# R7FA4T1BB register map
Vendor: Renesas Electronics Corporation; Series: RA4; File version: 1.30.00
CPU: CM33 r0p4, little endian, MPU, FPU, VTOR, 4 interrupt priority bits, 96 interrupts
Registers are 32-bit, read-write, reset 0x0 unless marked. A register's access mark holds for its fields unless they carry their own. Offsets are from the block's base; [hi:lo] are bit positions; {n}, {i} and the like mark numbered series; 'fields as' and 'values as' point back to an identical list.

## CANFD_B — CANFD
Base 0x400B0000
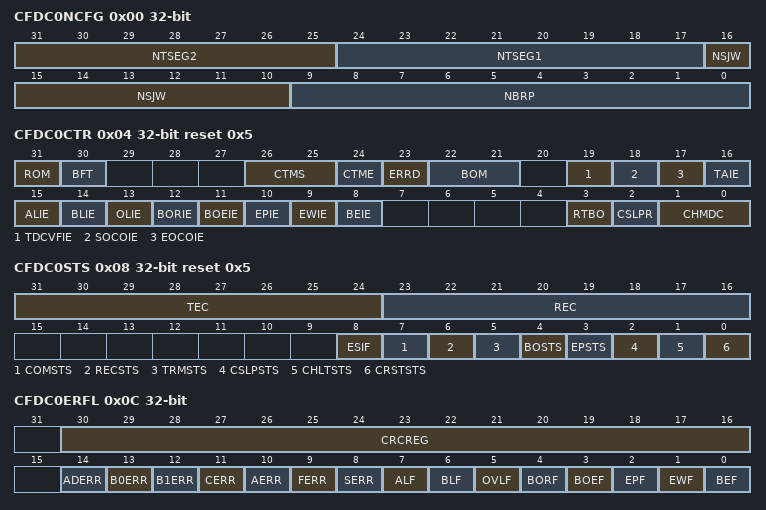
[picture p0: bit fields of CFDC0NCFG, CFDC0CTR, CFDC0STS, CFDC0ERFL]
0x00 CFDC0NCFG — Channel 0 Nominal Bitrate Configuration Register
  [31:25] NTSEG2 — Timing Segment 2
  [24:17] NTSEG1 — Timing Segment 1
  [16:10] NSJW — Resynchronization Jump Width
  [9:0] NBRP — Channel Nominal Baud Rate Prescaler
0x04 CFDC0CTR reset 0x5 — Channel 0 Control Register
  [31] ROM — Restricted Operation Mode
    0=Restricted operation mode disabled; 1=Restricted operation mode enabled
  [30] BFT — Bit Flip Test
    0=First data bit of reception stream not inverted; 1=First data bit of reception stream inverted
  [26:25] CTMS — Channel Test Mode Select
    0=Basic test mode; 1=Listen-only mode; 2=Self-test mode 0 (External loopback mode); 3=Self-test mode 1 (Internal loopback mode)
  [24] CTME — Channel Test Mode Enable
    0=Channel test mode disabled; 1=Channel test mode enabled
  [23] ERRD — Channel Error Display
    0=Only the first set of error codes displayed; 1=Accumulated error codes displayed
  [22:21] BOM — Channel Bus-Off Mode
    0=Normal mode (comply with ISO 11898-1); 1=Entry to Halt mode automatically at bus-off start; 2=Entry to Halt mode automatically at bus-off end; 3=Entry to Halt mode (during bus-off recovery period) by software
  [19] TDCVFIE — Transceiver Delay Compensation Violation Interrupt Enable
    0=Transceiver delay compensation violation interrupt disabled; 1=Transceiver delay compensation violation interrupt enabled
  [18] SOCOIE — Successful Occurrence Counter Overflow Interrupt Enable
    0=Successful occurrence counter overflow interrupt disabled; 1=Successful occurrence counter overflow interrupt enabled
  [17] EOCOIE — Error Occurrence Counter Overflow Interrupt Enable
    0=Error occurrence counter overflow interrupt disabled; 1=Error occurrence counter overflow interrupt enabled
  [16] TAIE — Transmission Abort Interrupt Enable
    0=TX abort interrupt disabled; 1=TX abort interrupt enabled
  [15] ALIE — Arbitration Lost Interrupt Enable
    0=Arbitration lost interrupt disabled; 1=Arbitration lost interrupt enabled
  [14] BLIE — Bus Lock Interrupt Enable
    0=Bus lock interrupt disabled; 1=Bus lock interrupt enabled
  [13] OLIE — Overload Interrupt Enable
    0=Overload interrupt disabled; 1=Overload interrupt enabled
  [12] BORIE — Bus-Off Recovery Interrupt Enable
    0=Bus-off recovery interrupt disabled; 1=Bus-off recovery interrupt enabled
  [11] BOEIE — Bus-Off Entry Interrupt Enable
    0=Bus-off entry interrupt disabled; 1=Bus-off entry interrupt enabled
  [10] EPIE — Error Passive Interrupt Enable
    0=Error passive interrupt disabled; 1=Error passive interrupt enabled
  [9] EWIE — Error Warning Interrupt Enable
    0=Error warning interrupt disabled; 1=Error warning interrupt enabled
  [8] BEIE — Bus Error Interrupt Enable
    0=Bus error interrupt disabled; 1=Bus error interrupt enabled
  [3] RTBO — Return from Bus-Off
    0=Channel is not forced to return from bus-off; 1=Channel is forced to return from bus-off
  [2] CSLPR — Channel Sleep Request
    0=Channel sleep request disabled; 1=Channel sleep request enabled
  [1:0] CHMDC — Channel Mode Control
    0=Channel operation mode request; 1=Channel reset request; 2=Channel halt request; 3=Keep current value
0x08 CFDC0STS reset 0x5 — Channel 0 Status Register
  [31:24] TEC ro — Transmission Error Count
  [23:16] REC ro — Reception Error Count
  [8] ESIF — Error State Indication Flag
    0=No CANFD message has been received when the ESI flag was set; 1=At least one CANFD message was received when the ESI flag was set
  [7] COMSTS ro — Channel Communication Status
    0=Channel is not ready for communication; 1=Channel is ready for communication
  [6] RECSTS ro — Channel Receive Status
    0=Channel is not receiving; 1=Channel is receiving
  [5] TRMSTS ro — Channel Transmit Status
    0=Channel is not transmitting; 1=Channel is transmitting
  [4] BOSTS ro — Channel Bus-Off Status
    0=Channel not in bus-off state; 1=Channel in bus-off state
  [3] EPSTS ro — Channel Error Passive Status
    0=Channel not in error passive state; 1=Channel in error passive state
  [2] CSLPSTS ro — Channel Sleep Status
    0=Channel not in Sleep mode; 1=Channel in Sleep mode
  [1] CHLTSTS ro — Channel Halt Status
    0=Channel not in Halt mode; 1=Channel in Halt mode
  [0] CRSTSTS ro — Channel Reset Status
    0=Channel not in Reset mode; 1=Channel in Reset mode
0x0C CFDC0ERFL — Channel 0 Error Flag Register
  [30:16] CRCREG ro — CRC Register value
  [14] ADERR — Acknowledge Delimiter Error
    0=Channel acknowledge delimiter error not detected; 1=Channel acknowledge delimiter error detected
  [13] B0ERR — Bit 0 Error
    0=Channel bit 0 error not detected; 1=Channel bit 0 error detected
  [12] B1ERR — Bit 1 Error
    0=Channel bit 1 error not detected; 1=Channel bit 1 error detected
  [11] CERR — CRC Error
    0=Channel CRC error not detected; 1=Channel CRC error detected
  [10] AERR — Acknowledge Error
    0=Channel acknowledge error not detected; 1=Channel acknowledge error detected
  [9] FERR — Form Error
    0=Channel form error not detected; 1=Channel form error detected
  [8] SERR — Stuff Error
    0=Channel stuff error not detected; 1=Channel stuff error detected
  [7] ALF — Arbitration Lost Flag
    0=Channel arbitration lost not detected; 1=Channel arbitration lost detected
  [6] BLF — Bus Lock Flag
    0=Channel bus lock not detected; 1=Channel bus lock detected
  [5] OVLF — Overload Flag
    0=Channel overload not detected; 1=Channel overload detected
  [4] BORF — Bus-Off Recovery Flag
    0=Channel bus-off recovery not detected; 1=Channel bus-off recovery detected
  [3] BOEF — Bus-Off Entry Flag
    0=Channel bus-off entry not detected; 1=Channel bus-off entry detected
  [2] EPF — Error Passive Flag
    0=Channel error passive not detected; 1=Channel error passive detected
  [1] EWF — Error Warning Flag
    0=Channel error warning not detected; 1=Channel error warning detected
  [0] BEF — Bus Error Flag
    0=Channel bus error not detected; 1=Channel bus error detected
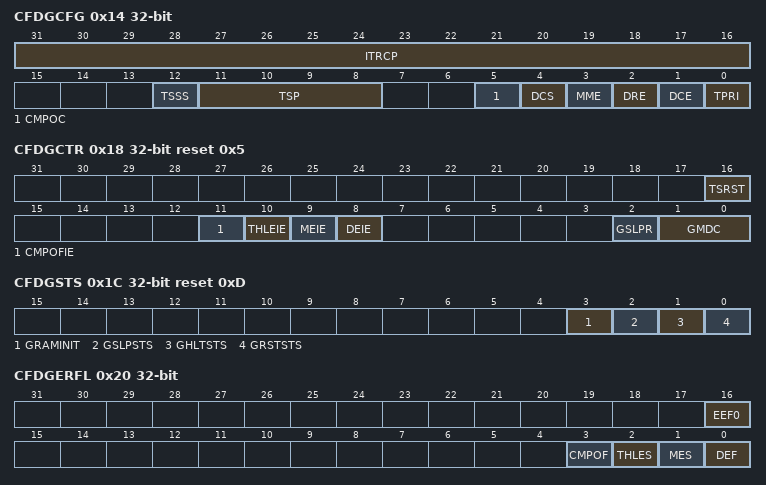
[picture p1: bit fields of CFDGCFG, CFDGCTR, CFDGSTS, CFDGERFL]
0x14 CFDGCFG — Global Configuration Register
  [31:16] ITRCP — Interval Timer Reference Clock Prescaler
  [12] TSSS — Timestamp Source Select
    0=Source clock for timestamp counter is peripheral clock; 1=Source clock for timestamp counter is bit time clock
  [11:8] TSP — Timestamp Prescaler
  [5] CMPOC — CANFD Message Payload Overflow Configuration
    0=Message is rejected; 1=Message payload is cut to fit to configured message size
  [4] DCS — Data Link Controller Clock Select
    0=Internal clean clock; 1=External clock source connected to CANMCLK pin
  [3] MME — Mirror Mode Enable
    0=Mirror mode disabled; 1=Mirror mode enabled
  [2] DRE — DLC Replacement Enable
    0=DLC replacement disabled; 1=DLC replacement enabled
  [1] DCE — DLC Check Enable
    0=DLC check disabled; 1=DLC check enabled
  [0] TPRI — Transmission Priority
    0=ID priority; 1=Message buffer number priority
0x18 CFDGCTR reset 0x5 — Global Control Register
  [16] TSRST — Timestamp Reset
    0=Timestamp not reset; 1=Timestamp reset
  [11] CMPOFIE — CANFD Message Payload Overflow Flag Interrupt Enable
    0=CANFD message payload overflow flag interrupt disabled; 1=CANFD message payload overflow flag interrupt enabled
  [10] THLEIE — TX History List Entry Lost Interrupt Enable
    0=TX history list entry lost interrupt disabled; 1=TX history list entry lost interrupt enabled
  [9] MEIE — Message Lost Error Interrupt Enable
    0=Message lost error interrupt disabled; 1=Message lost error interrupt enabled
  [8] DEIE — DLC Check Interrupt Enable
    0=DLC check interrupt disabled; 1=DLC check interrupt enabled
  [2] GSLPR — Global Sleep Request
    0=Global sleep request disabled; 1=Global sleep request enabled
  [1:0] GMDC — Global Mode Control
    0=Global operation mode request; 1=Global reset mode request; 2=Global halt mode request; 3=Keep current value
0x1C CFDGSTS ro reset 0xD — Global Status Register
  [3] GRAMINIT — Global RAM Initialization
    0=RAM initialization is complete; 1=RAM initialization is ongoing
  [2] GSLPSTS — Global Sleep Status
    0=Not in Sleep mode; 1=In Sleep mode
  [1] GHLTSTS — Global Halt Status
    0=Not in Halt mode; 1=In Halt mode
  [0] GRSTSTS — Global Reset Status
    0=Not in Reset mode; 1=In Reset mode
0x20 CFDGERFL — Global Error Flag Register
  [16] EEF0 — ECC Error Flag
    0=ECC error not detected during TX-SCAN; 1=ECC error detected during TX-SCAN
  [3] CMPOF — CANFD Message Payload Overflow Flag
    0=CANFD message payload overflow not detected; 1=CANFD message payload overflow detected
  [2] THLES ro — TX History List Entry Lost Error Status
    0=TX history list entry lost error not detected; 1=TX history list entry lost error detected
  [1] MES ro — Message Lost Error Status
    0=Message lost error not detected; 1=Message lost error detected
  [0] DEF — DLC Error Flag
    0=DLC error not detected; 1=DLC error detected
0x24 CFDGTSC ro — Global Timestamp Counter Register
  [15:0] TS — Timestamp value
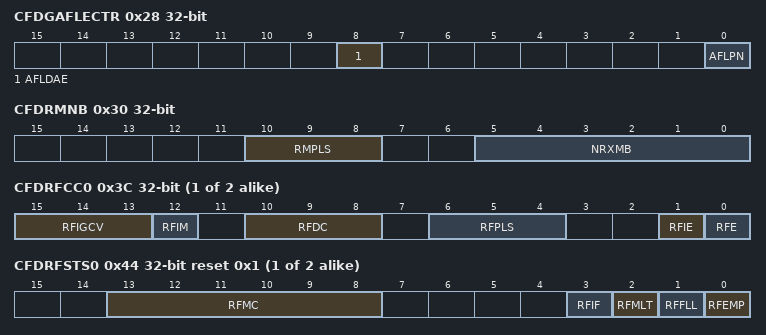
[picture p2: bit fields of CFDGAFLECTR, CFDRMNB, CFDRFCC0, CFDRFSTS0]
0x28 CFDGAFLECTR — Global Acceptance Filter List Entry Control Register
  [8] AFLDAE — Acceptance Filter List Data Access Enable
    0=Acceptance Filter List data access disabled; 1=Acceptance Filter List data access enabled
  [0] AFLPN — Acceptance Filter List Page Number
0x2C CFDGAFLCFG — Global Acceptance Filter List Configuration Register
  [21:16] RNC0 — Rule Number
0x30 CFDRMNB — RX Message Buffer Number Register
  [10:8] RMPLS — Reception Message Buffer Payload Data Size
    0=8 bytes; 1=12 bytes; 2=16 bytes; 3=20 bytes; 4=24 bytes; 5=32 bytes; 6=48 bytes; 7=64 bytes
  [5:0] NRXMB — Number of RX Message Buffers
0x34 CFDRMND — RX Message Buffer New Data Register
  [31:0] RMNS — RX Message Buffer New Data Status
    0=New data not stored in corresponding RX message buffer; 1=New data stored in corresponding RX message buffer
0x38 CFDRMIEC — RX Message Buffer Interrupt Enable Configuration Register
  [31:0] RMIEg — RX Message Buffer Interrupt Enable
    0=RX Message Buffer Interrupt disabled for corresponding RX message buffer; 1=RX Message Buffer Interrupt enabled for corresponding RX message buffer
{0x3C+4i} CFDRFCC{i} (i=0..1) — RX FIFO Configuration/Control Registers {i}
  [15:13] RFIGCV — RX FIFO Interrupt Generation Counter Value
    0=Interrupt generated when FIFO is 1/8th full; 1=Interrupt generated when FIFO is 1/4th full; 2=Interrupt generated when FIFO is 3/8th full; 3=Interrupt generated when FIFO is 1/2 full; 4=Interrupt generated when FIFO is 5/8th full; 5=Interrupt generated when FIFO is 3/4th full; 6=Interrupt generated when FIFO is 7/8th full; 7=Interrupt generated when FIFO is full
  [12] RFIM — RX FIFO Interrupt Mode
    0=Interrupt generated when RX FIFO counter reaches RFIGCV value from values smaller than RFIGCV; 1=Interrupt generated at the end of every received message storage
  [10:8] RFDC — RX FIFO Depth Configuration
    0=FIFO Depth = 0 message; 1=FIFO Depth = 4 messages; 2=FIFO Depth = 8 messages; 3=FIFO Depth = 16 messages; 4=FIFO Depth = 32 messages; 5=FIFO Depth = 48 messages
  [6:4] RFPLS — Rx FIFO Payload Data Size Configuration
    values as CFDRMNB.RMPLS
  [1] RFIE — RX FIFO Interrupt Enable
    0=FIFO interrupt generation disabled; 1=FIFO interrupt generation enabled
  [0] RFE — RX FIFO Enable
    0=FIFO disabled; 1=FIFO enabled
{0x44+4i} CFDRFSTS{i} (i=0..1) reset 0x1 — RX FIFO Status Registers {i}
  [13:8] RFMC ro — RX FIFO Message Count
  [3] RFIF — RX FIFO Interrupt Flag
    0=FIFO interrupt condition not satisfied; 1=FIFO interrupt condition satisfied
  [2] RFMLT — RX FIFO Message Lost
    0=No message lost in FIFO; 1=FIFO message lost
  [1] RFFLL ro — RX FIFO Full
    0=FIFO not full; 1=FIFO full
  [0] RFEMP ro — RX FIFO Empty
    0=FIFO not empty; 1=FIFO empty
{0x4C+4i} CFDRFPCTR{i} (i=0..1) wo — RX FIFO Pointer Control Registers {i}
  [7:0] RFPC — RX FIFO Pointer Control
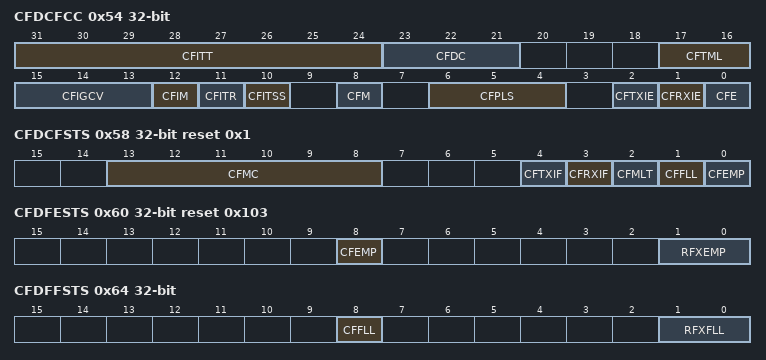
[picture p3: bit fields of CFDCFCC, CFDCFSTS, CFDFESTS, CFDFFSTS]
0x54 CFDCFCC — Common FIFO Configuration/Control Register
  [31:24] CFITT — Common FIFO Interval Transmission Time
  [23:21] CFDC — Common FIFO Depth Configuration
    0=FIFO Depth = 0 message; 1=FIFO Depth = 4 messages; 2=FIFO Depth = 8 messages; 3=FIFO Depth = 16 messages; 4=FIFO Depth = 32 messages; 5=FIFO Depth = 48 messages; 6=FIFO Depth = Reserved; 7=FIFO Depth = Reserved
  [17:16] CFTML — Common FIFO TX Message Buffer Link
  [15:13] CFIGCV — Common FIFO Interrupt Generation Counter Value
    values as CFDRFCC0.RFIGCV
  [12] CFIM — Common FIFO Interrupt Mode
    0=RX FIFO mode: RX interrupt generated when Common FIFO counter reaches CFIGCV value from a lower value TX FIFO mode: TX interrupt generated when Common FIFO transmits the last message successfully; 1=RX FIFO mode: RX interrupt generated at the end of every received message storage TX FIFO mode: interrupt generated for every successfully transmitted message
  [11] CFITR — Common FIFO Interval Timer Resolution
    0=Reference clock period × 1; 1=Reference clock period × 10
  [10] CFITSS — Common FIFO Interval Timer Source Select
    0=Reference clock (× 1 / × 10 period); 1=Bit time clock of related channel (FIFO is linked to fixed channel)
  [8] CFM — Common FIFO Mode
    0=RX FIFO mode; 1=TX FIFO mode
  [6:4] CFPLS — Common FIFO Payload Data Size Configuration
    values as CFDRMNB.RMPLS
  [2] CFTXIE — Common FIFO TX Interrupt Enable
    0=FIFO interrupt generation disabled for Frame TX; 1=FIFO interrupt generation enabled for Frame TX
  [1] CFRXIE — Common FIFO RX Interrupt Enable
    0=FIFO interrupt generation disabled for Frame RX; 1=FIFO interrupt generation enabled for Frame RX
  [0] CFE — Common FIFO Enable
    0=FIFO disabled; 1=FIFO enabled
0x58 CFDCFSTS reset 0x1 — Common FIFO Status Register
  [13:8] CFMC ro — Common FIFO Message Count
  [4] CFTXIF — Common TX FIFO Interrupt Flag
    0=FIFO interrupt condition not satisfied after frame transmission; 1=FIFO Interrupt condition satisfied after frame transmission
  [3] CFRXIF — Common RX FIFO Interrupt Flag
    0=FIFO interrupt condition not satisfied after frame reception; 1=FIFO interrupt condition satisfied after frame reception
  [2] CFMLT — Common FIFO Message Lost
    0=Number of message lost in FIFO; 1=FIFO message lost
  [1] CFFLL ro — Common FIFO Full
    0=FIFO not full; 1=FIFO full
  [0] CFEMP ro — Common FIFO Empty
    0=FIFO not empty; 1=FIFO empty
0x5C CFDCFPCTR wo — Common FIFO Pointer Control Register
  [7:0] CFPC — Common FIFO Pointer Control
0x60 CFDFESTS ro reset 0x103 — FIFO Empty Status Register
  [8] CFEMP — Common FIFO Empty Status
    0=Corresponding FIFO not empty; 1=Corresponding FIFO empty
  [1:0] RFXEMP — RX FIFO Empty Status
    0=Corresponding FIFO not empty; 1=Corresponding FIFO empty
0x64 CFDFFSTS ro — FIFO Full Status Register
  [8] CFFLL — Common FIF0 Full Status
    0=Corresponding FIFO not full; 1=Corresponding FIFO full
  [1:0] RFXFLL — RX FIF0 Full Status
    0=Corresponding FIFO not full; 1=Corresponding FIFO full
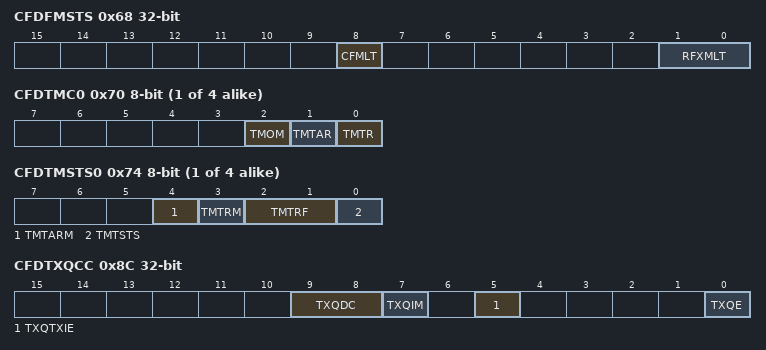
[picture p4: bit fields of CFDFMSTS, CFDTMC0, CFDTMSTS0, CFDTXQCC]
0x68 CFDFMSTS ro — FIFO Message Lost Status Register
  [8] CFMLT — Common FIFO Message Lost Status
    0=Corresponding FIFO Message Lost flag not set; 1=Corresponding FIFO Message Lost flag set
  [1:0] RFXMLT — RX FIFO Message Lost Status
    values as CFMLT
0x6C CFDRFISTS ro — RX FIFO Interrupt Flag Status Register
  [1:0] RFXIF — RX FIFO[x] Interrupt Flag Status
    0=Corresponding RX FIFO Interrupt flag not set; 1=Corresponding RX FIFO Interrupt flag set
{0x70+i} CFDTMC{i} (i=0..3) 8-bit — TX Message Buffer Control Registers {i}
  [2] TMOM — TX Message Buffer One-shot Mode
    0=TX message buffer not configured in one-shot mode; 1=TX message buffer configured in one-shot mode
  [1] TMTAR — TX Message Buffer Transmission Abort Request
    0=TX message buffer transmission request abort not requested; 1=TX message buffer transmission request abort requested
  [0] TMTR — TX Message Buffer Transmission Request
    0=TX Message buffer transmission not requested; 1=TX message buffer transmission requested
{0x74+i} CFDTMSTS{i} (i=0..3) 8-bit — TX Message Buffer Status Registers {i}
  [4] TMTARM ro — TX Message Buffer Transmission Abort Request Mirrored
    values as CFDTMC0.TMTAR
  [3] TMTRM ro — TX Message Buffer Transmission Request Mirrored
    0=TX message buffer transmission not requested; 1=TX message buffer transmission requested
  [2:1] TMTRF — TX Message Buffer Transmission Result Flag
    0=No result; 1=Transmission aborted from the TX message buffer; 2=Transmission successful from the TX message buffer and transmission abort was not requested; 3=Transmission successful from the TX message buffer and transmission abort was requested
  [0] TMTSTS ro — TX Message Buffer Transmission Status
    0=No on-going transmission; 1=On-going transmission
0x78 CFDTMTRSTS ro — TX Message Buffer Transmission Request Status Register
  [3:0] CFDTMTRSTS — TX Message Buffer Transmission Request Status
    0=Transmission not requested for corresponding TX message buffer; 1=Transmission requested for corresponding TX message buffer
0x7C CFDTMTARSTS ro — TX Message Buffer Transmission Abort Request Status Register
  [3:0] CFDTMTARSTS — TX Message Buffer Transmission Abort Request Status
    0=Transmission abort not requested for corresponding TX message buffer; 1=Transmission abort requested for corresponding TX message buffer
0x80 CFDTMTCSTS ro — TX Message Buffer Transmission Completion Status Register
  [3:0] CFDTMTCSTS — TX Message Buffer Transmission Completion Status
    0=Transmission not complete for corresponding TX message buffer; 1=Transmission completed for corresponding TX message buffer
0x84 CFDTMTASTS ro — TX Message Buffer Transmission Abort Status Register
  [3:0] CFDTMTASTS — TX Message Buffer Transmission Abort Status
    0=Transmission not aborted for corresponding TX message buffer; 1=Transmission aborted for corresponding TX message buffer
0x88 CFDTMIEC — TX Message Buffer Interrupt Enable Configuration Register
  [3:0] TMIEg — TX Message Buffer Interrupt Enable
    0=TX message buffer interrupt disabled for corresponding TX message buffer; 1=TX message buffer interrupt enabled for corresponding TX message buffer
0x8C CFDTXQCC — TX Queue Configuration/Control Register
  [9:8] TXQDC — TX Queue Depth Configuration
    0=0 messages; 16=3 messages; 17=4 messages
  [7] TXQIM — TX Queue Interrupt Mode
    0=When the last message is successfully transmitted; 1=At every successful transmission
  [5] TXQTXIE — TX Queue TX Interrupt Enable
    0=TX Queue TX interrupt disabled; 1=TX Queue TX interrupt enabled
  [0] TXQE — TX Queue Enable
    0=TX Queue disabled; 1=TX Queue enabled
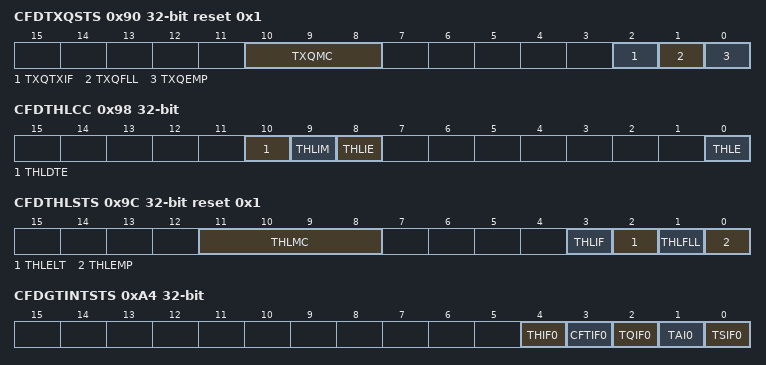
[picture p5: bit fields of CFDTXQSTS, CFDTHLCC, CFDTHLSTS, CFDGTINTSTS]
0x90 CFDTXQSTS reset 0x1 — TX Queue Status Register
  [10:8] TXQMC ro — TX Queue Message Count
  [2] TXQTXIF — TX Queue TX Interrupt Flag
    0=TX Queue interrupt condition not satisfied after a frame TX; 1=TX Queue interrupt condition satisfied after a frame TX
  [1] TXQFLL ro — TX Queue Full
    0=TX Queue not full; 1=TX Queue full
  [0] TXQEMP ro — TX Queue Empty
    0=TX Queue not empty; 1=TX Queue empty
0x94 CFDTXQPCTR — TX Queue Pointer Control Register
  [7:0] TXQPC wo — TX Queue Pointer Control
0x98 CFDTHLCC — TX History List Configuration/Control Register
  [10] THLDTE — TX History List Dedicated TX Enable
    0=TX FIFO + TX Queue; 1=Flat TX MB + TX FIFO + TX Queue
  [9] THLIM — TX History List Interrupt Mode
    0=Interrupt generated if TX History List level reaches ¾ of the TX History List depth; 1=Interrupt generated for every successfully stored entry
  [8] THLIE — TX History List Interrupt Enable
    0=TX History List Interrupt disabled; 1=TX History List Interrupt enabled
  [0] THLE — TX History List Enable
    0=TX History List disabled; 1=TX History List enabled
0x9C CFDTHLSTS reset 0x1 — TX History List Status Register
  [11:8] THLMC ro — TX History List Message Count
  [3] THLIF — TX History List Interrupt Flag
    0=TX History List interrupt condition not satisfied; 1=TX History List interrupt condition satisfied
  [2] THLELT — TX History List Entry Lost
    0=No entry lost in TX History List; 1=TX History List entry Lost
  [1] THLFLL ro — TX History List Full
    0=TX History List not full; 1=TX History List full
  [0] THLEMP ro — TX History List Empty
    0=TX History List not empty; 1=TX History List empty
0xA0 CFDTHLPCTR wo — TX History List Pointer Control Register
  [7:0] THLPC — TX History List Pointer Control
0xA4 CFDGTINTSTS ro — Global TX Interrupt Status Register
  [4] THIF0 — TX History List Interrupt
    0=Channel n TX History List Interrupt flag not set; 1=Channel n TX History List Interrupt flag set
  [3] CFTIF0 — COM FIFO TX Mode Interrupt Flag
    0=Channel n COM FIFO TX Mode Interrupt flag not set; 1=Channel n COM FIFO TX Mode Interrupt flag set
  [2] TQIF0 — TX Queue Interrupt Flag
    0=Channel n TX Queue Interrupt flag not set; 1=Channel n TX Queue Interrupt flag set
  [1] TAI0 — TX Abort Interrupt Flag
    0=Channel n TX Abort Interrupt flag not set; 1=Channel n TX Abort Interrupt flag set
  [0] TSIF0 — TX Successful Interrupt Flag
    0=Channel n TX Successful Interrupt flag not set; 1=Channel n TX Successful Interrupt flag set
0xA8 CFDGTSTCFG — Global Test Configuration Register
  [19:16] RTMPS — RAM Test Mode Page Select
0xAC CFDGTSTCTR — Global Test Control Register
  [2] RTME — RAM Test Mode Enable
    0=RAM test mode disabled; 1=RAM test mode enabled
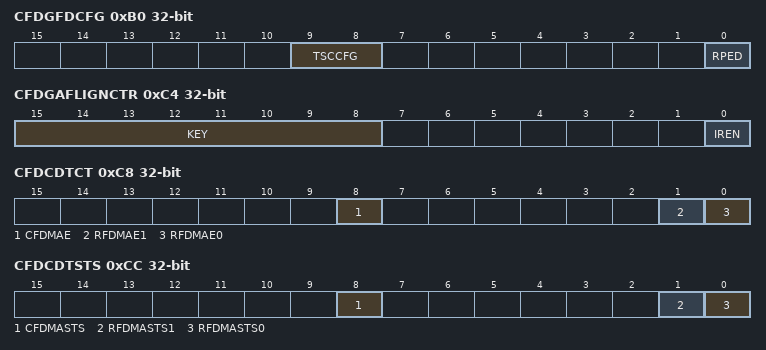
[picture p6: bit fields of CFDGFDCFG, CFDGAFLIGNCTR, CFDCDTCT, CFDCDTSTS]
0xB0 CFDGFDCFG — Global FD Configuration Register
  [9:8] TSCCFG — Timestamp Capture Configuration
    0=Timestamp capture at the sample point of SOF (start of frame); 1=Timestamp capture at frame valid indication; 2=Timestamp capture at the sample point of RES bit
  [0] RPED — RES Bit Protocol Exception Disable
    0=Protocol exception event detection enabled; 1=Protocol exception event detection disabled
0xB8 CFDGLOCKK wo — Global Lock Key Register
  [15:0] LOCK — Lock Key
0xC0 CFDGAFLIGNENT — Global AFL Ignore Entry Register
  [4:0] IRN — Ignore Rule Number
0xC4 CFDGAFLIGNCTR — Global AFL Ignore Control Register
  [15:8] KEY wo — Key Code
  [0] IREN — Ignore Rule Enable
    0=AFL entry number is not ignored; 1=AFL entry number is ignored
0xC8 CFDCDTCT — DMA Transfer Control Register
  [all] fields
    0=DMA transfer request disabled; 1=DMA transfer request enabled
  [8] CFDMAE — DMA Transfer Enable for Common FIFO 0
  [1] RFDMAE1 — DMA Transfer Enable for RXFIFO 1
  [0] RFDMAE0 — DMA Transfer Enable for RXFIFO 0
0xCC CFDCDTSTS ro — DMA Transfer Status Register
  [all] fields
    0=DMA transfer stopped; 1=DMA transfer on going
  [8] CFDMASTS — DMA Transfer Status only for Common FIFO
  [1] RFDMASTS1 — DMA Transfer Status for RX FIFO 1
  [0] RFDMASTS0 — DMA Transfer Status for RX FIFO 0
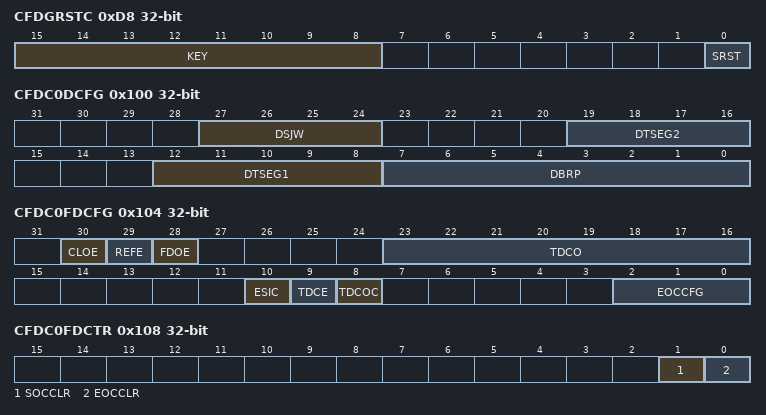
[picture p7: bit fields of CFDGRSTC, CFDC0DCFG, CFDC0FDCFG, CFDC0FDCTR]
0xD8 CFDGRSTC — Global SW reset Register
  [15:8] KEY wo — Key Code
  [0] SRST — SW Reset
    0=Normal state; 1=SW reset state
0x100 CFDC0DCFG — Channel 0 Data Bitrate Configuration Register
  [27:24] DSJW — Resynchronization Jump Width
  [19:16] DTSEG2 — Timing Segment 2
  [12:8] DTSEG1 — Timing Segment 1
  [7:0] DBRP — Channel Data Baud Rate Prescaler
0x104 CFDC0FDCFG — Channel 0 CANFD Configuration Register
  [30] CLOE — Classical CAN Enable
    0=Classical CAN mode disabled; 1=Classical CAN mode enabled
  [29] REFE — RX Edge Filter Enable
    0=RX edge filter disabled; 1=RX edge filter enabled
  [28] FDOE — FD-Only Enable
    0=FD-only mode disabled; 1=FD-only mode enabled
  [23:16] TDCO — Transceiver Delay Compensation Offset
  [10] ESIC — Error State Indication Configuration
    0=The ESI bit in the frame represents the error state of the node itself; 1=The ESI bit in the frame represents the error state of the message buffer if the node itself is not in error passive. If the node is in error passive, then the ESI bit is driven by the node itself.
  [9] TDCE — Transceiver Delay Compensation Enable
    0=Transceiver delay compensation disabled; 1=Transceiver delay compensation enabled
  [8] TDCOC — Transceiver Delay Compensation Offset Configuration
    0=Measured + offset; 1=Offset-only
  [2:0] EOCCFG — Error Occurrence Counter Configuration
    0=All transmitter or receiver CAN frames; 1=All transmitter CAN frames; 2=All receiver CAN frames; 4=Only transmitter or receiver CANFD data-phase (fast bits); 5=Only transmitter CANFD data-phase (fast bits); 6=Only receiver CANFD data-phase (fast bits)
0x108 CFDC0FDCTR — Channel 0 CANFD Control Register
  [1] SOCCLR — Successful Occurrence Counter Clear
    0=No successful occurrence counter clear; 1=Clear successful occurrence counter
  [0] EOCCLR — Error Occurrence Counter Clear
    0=No error occurrence counter clear; 1=Clear error occurrence counter
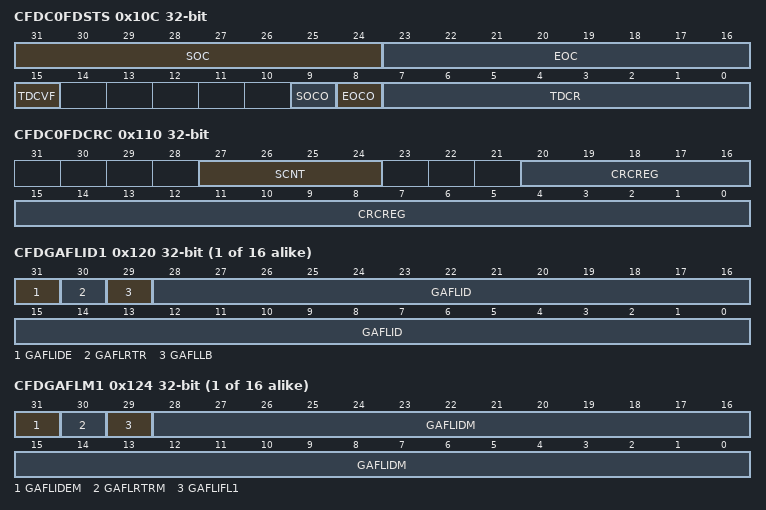
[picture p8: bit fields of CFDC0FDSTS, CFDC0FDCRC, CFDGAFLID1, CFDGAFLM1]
0x10C CFDC0FDSTS — Channel 0 CANFD Status Register
  [31:24] SOC ro — Successful occurrence counter
  [23:16] EOC ro — Error Occurrence Counter
  [15] TDCVF — Transceiver Delay Compensation Violation Flag
    0=Transceiver delay compensation violation has not occurred; 1=Transceiver delay compensation violation has occurred
  [9] SOCO — Successful Occurrence Counter Overflow
    0=Successful occurrence counter has not overflowed; 1=Successful occurrence counter has overflowed
  [8] EOCO — Error Occurrence Counter Overflow
    0=Error occurrence counter has not overflowed; 1=Error occurrence counter has overflowed
  [7:0] TDCR ro — Transceiver Delay Compensation Result
0x110 CFDC0FDCRC — Channel 0 CANFD CRC Register
  [27:24] SCNT ro — Stuff bit count
  [20:0] CRCREG ro — CRC Register value
{0x110+0x10*i} CFDGAFLID{i} (i=1..16) — Global Acceptance Filter List ID Registers
  [31] GAFLIDE — Global Acceptance Filter List Entry IDE Field
    0=Standard identifier of rule entry ID is valid for acceptance filtering; 1=Extended identifier of rule entry ID is valid for acceptance filtering
  [30] GAFLRTR — Global Acceptance Filter List Entry RTR Field
    0=Data frame; 1=Remote frame
  [29] GAFLLB — Global Acceptance Filter List Entry Loopback Configuration
    0=Global Acceptance Filter List entry ID for acceptance filtering with attribute RX; 1=Global Acceptance Filter List entry ID for acceptance filtering with attribute TX
  [28:0] GAFLID — Global Acceptance Filter List Entry ID Field
{0x114+0x10*i} CFDGAFLM{i} (i=1..16) — Global Acceptance Filter List Mask Registers
  [31] GAFLIDEM — Global Acceptance Filter List IDE Mask
    0=IDE bit is not used for ID matching; 1=IDE bit is used for ID matching
  [30] GAFLRTRM — Global Acceptance Filter List Entry RTR Mask
    0=RTR bit is not used for ID matching; 1=RTR bit is used for ID matching
  [29] GAFLIFL1 — Global Acceptance Filter List Information Label 1
  [28:0] GAFLIDM — Global Acceptance Filter List ID Mask Field
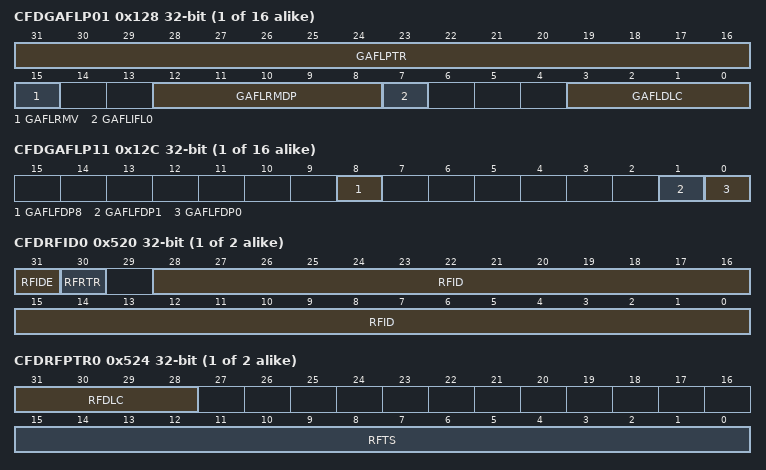
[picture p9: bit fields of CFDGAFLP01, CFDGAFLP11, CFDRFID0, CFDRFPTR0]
{0x118+0x10*i} CFDGAFLP0{i} (i=1..16) — Global Acceptance Filter List Pointer 0 Registers
  [31:16] GAFLPTR — Global Acceptance Filter List Pointer
  [15] GAFLRMV — Global Acceptance Filter List RX Message Buffer Valid
    0=Single message buffer direction pointer is invalid; 1=Single message buffer direction pointer is valid
  [12:8] GAFLRMDP — Global Acceptance Filter List RX Message Buffer Direction Pointer
  [7] GAFLIFL0 — Global Acceptance Filter List Information Label 0
  [3:0] GAFLDLC — Global Acceptance Filter List DLC Field
{0x11C+0x10*i} CFDGAFLP1{i} (i=1..16) — Global Acceptance Filter List Pointer 1 Registers
  [8] GAFLFDP8 — Global Acceptance Filter List FIFO Direction Pointer
    0=Disable Common FIFO as target for reception; 1=Enable Common FIFO as target for reception
  [1] GAFLFDP1 — Global Acceptance Filter List FIFO Direction Pointer
    0=Disable RX FIFO 1 as target for reception; 1=Enable RX FIFO 1 as target for reception
  [0] GAFLFDP0 — Global Acceptance Filter List FIFO Direction Pointer
    0=Disable RX FIFO 0 as target for reception; 1=Enable RX FIFO 0 as target for reception
{0x280+4i} CFDRPGACC{i} (i=0..63) — RAM Test Page Access Registers {i}
  [31:0] RDTA — RAM Data Test Access
{0x520+0x4C*i} CFDRFID{i} (i=0..1) ro — RX FIFO Access ID Register {i}
  [31] RFIDE — RX FIFO Buffer IDE bit
    0=STD-ID has been received; 1=EXT-ID has been received
  [30] RFRTR — RX FIFO Buffer RTR bit
    0=Data frame; 1=Remote frame
  [28:0] RFID — RX FIFO Buffer ID Field
{0x524+0x4C*i} CFDRFPTR{i} (i=0..1) ro — RX FIFO Access Pointer Register {i}
  [31:28] RFDLC — RX FIFO Buffer DLC Field
  [15:0] RFTS — RX FIFO Timestamp Value
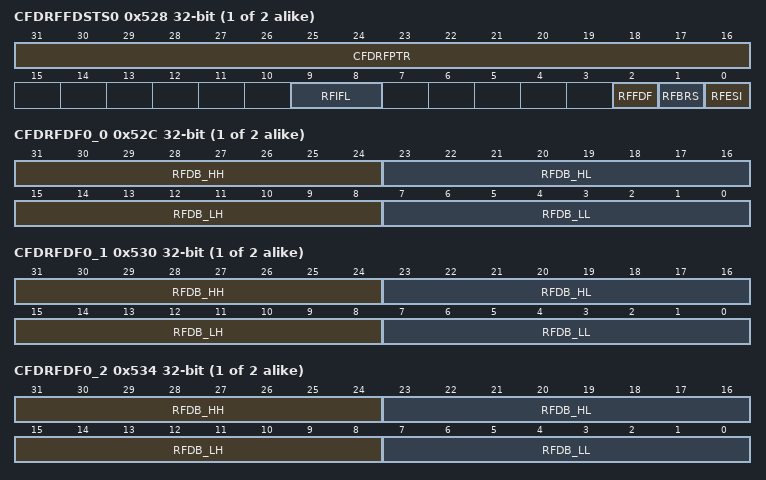
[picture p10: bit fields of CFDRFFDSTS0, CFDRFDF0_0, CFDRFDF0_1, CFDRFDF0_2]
{0x528+0x4C*i} CFDRFFDSTS{i} (i=0..1) ro — RX FIFO Access CANFD Status Register {i}
  [31:16] CFDRFPTR — RX FIFO Buffer Pointer Field
  [9:8] RFIFL — RX FIFO Buffer Information Label Field
  [2] RFFDF — CAN FD Format bit
    0=Non CANFD frame received; 1=CANFD frame received
  [1] RFBRS — Bit Rate Switch bit
    0=CANFD frame received with no bit rate switch; 1=CANFD frame received with bit rate switch
  [0] RFESI — Error State Indicator bit
    0=CANFD frame received from error active node; 1=CANFD frame received from error passive node
{0x52C+0x4C*i} CFDRFDF{i}_0 (i=0..1) ro — RX FIFO Access Data Field 0 Register {i}
  [31:24] RFDB_HH — RX FIFO Buffer Data Byte ((p × 4) + 3)
  [23:16] RFDB_HL — RX FIFO Buffer Data Byte ((p × 4) + 2)
  [15:8] RFDB_LH — RX FIFO Buffer Data Byte ((p × 4) + 1)
  [7:0] RFDB_LL — RX FIFO Buffer Data Byte (p × 4)
{0x530+0x4C*i} CFDRFDF{i}_1 (i=0..1) ro — RX FIFO Access Data Field 1 Register {i}
  fields as CFDRFDF0_0
{0x534+0x4C*i} CFDRFDF{i}_2 (i=0..1) ro — RX FIFO Access Data Field 2 Register {i}
  fields as CFDRFDF0_0
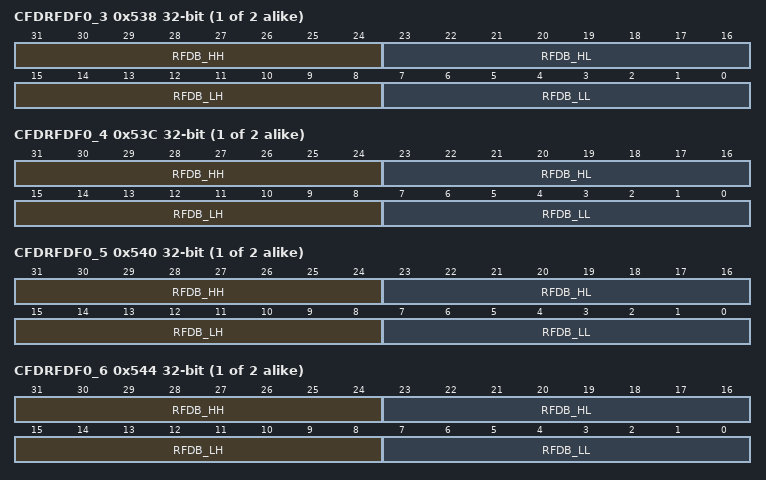
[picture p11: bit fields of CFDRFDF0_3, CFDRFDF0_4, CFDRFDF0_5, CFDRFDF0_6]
{0x538+0x4C*i} CFDRFDF{i}_3 (i=0..1) ro — RX FIFO Access Data Field 3 Register {i}
  fields as CFDRFDF0_0
{0x53C+0x4C*i} CFDRFDF{i}_4 (i=0..1) ro — RX FIFO Access Data Field 4 Register {i}
  fields as CFDRFDF0_0
{0x540+0x4C*i} CFDRFDF{i}_5 (i=0..1) ro — RX FIFO Access Data Field 5 Register {i}
  fields as CFDRFDF0_0
{0x544+0x4C*i} CFDRFDF{i}_6 (i=0..1) ro — RX FIFO Access Data Field 6 Register {i}
  fields as CFDRFDF0_0
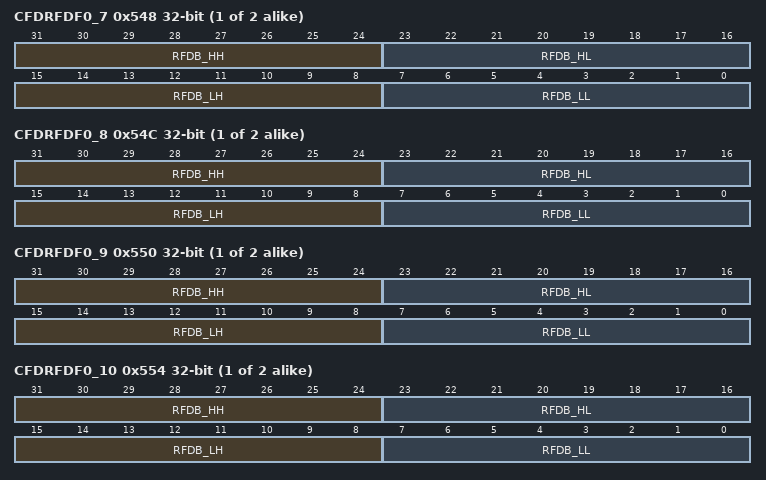
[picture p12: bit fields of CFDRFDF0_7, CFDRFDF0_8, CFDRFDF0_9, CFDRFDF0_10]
{0x548+0x4C*i} CFDRFDF{i}_7 (i=0..1) ro — RX FIFO Access Data Field 7 Register {i}
  fields as CFDRFDF0_0
{0x54C+0x4C*i} CFDRFDF{i}_8 (i=0..1) ro — RX FIFO Access Data Field 8 Register {i}
  fields as CFDRFDF0_0
{0x550+0x4C*i} CFDRFDF{i}_9 (i=0..1) ro — RX FIFO Access Data Field 9 Register {i}
  fields as CFDRFDF0_0
{0x554+0x4C*i} CFDRFDF{i}_10 (i=0..1) ro — RX FIFO Access Data Field 10 Register {i}
  fields as CFDRFDF0_0
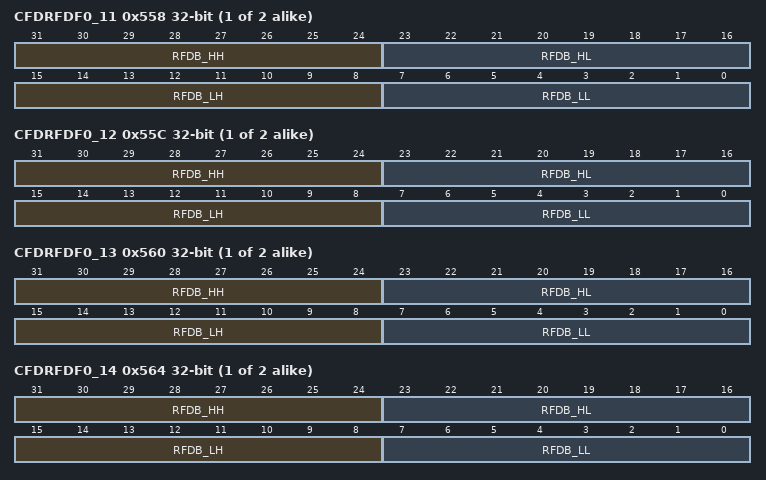
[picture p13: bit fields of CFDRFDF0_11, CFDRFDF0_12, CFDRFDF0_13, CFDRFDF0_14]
{0x558+0x4C*i} CFDRFDF{i}_11 (i=0..1) ro — RX FIFO Access Data Field 11 Register {i}
  fields as CFDRFDF0_0
{0x55C+0x4C*i} CFDRFDF{i}_12 (i=0..1) ro — RX FIFO Access Data Field 12 Register {i}
  fields as CFDRFDF0_0
{0x560+0x4C*i} CFDRFDF{i}_13 (i=0..1) ro — RX FIFO Access Data Field 13 Register {i}
  fields as CFDRFDF0_0
{0x564+0x4C*i} CFDRFDF{i}_14 (i=0..1) ro — RX FIFO Access Data Field 14 Register {i}
  fields as CFDRFDF0_0
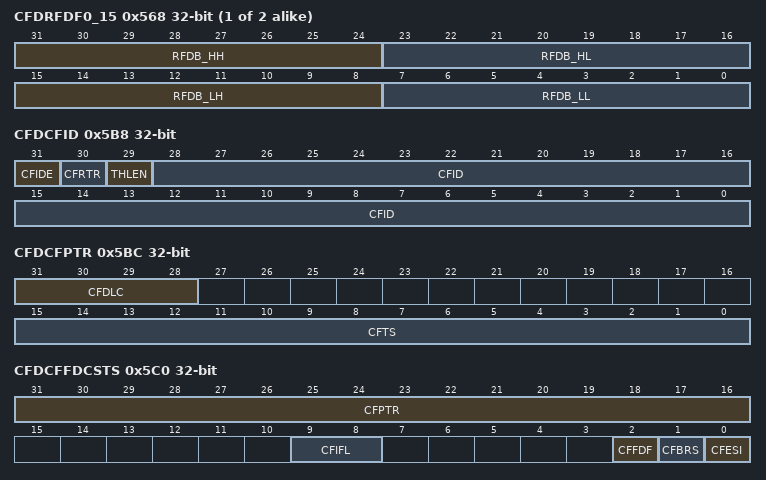
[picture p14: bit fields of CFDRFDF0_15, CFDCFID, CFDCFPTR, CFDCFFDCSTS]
{0x568+0x4C*i} CFDRFDF{i}_15 (i=0..1) ro — RX FIFO Access Data Field 15 Register {i}
  fields as CFDRFDF0_0
0x5B8 CFDCFID — Common FIFO Access ID Register
  [31] CFIDE — Common FIFO Buffer IDE Bit
    0=STD-ID will be transmitted or has been received; 1=EXT-ID will be transmitted or has been received
  [30] CFRTR — Common FIFO Buffer RTR Bit
    0=Data Frame; 1=Remote Frame
  [29] THLEN — THL Entry enable
    0=Entry will not be stored in THL after successful TX; 1=Entry will be stored in THL after successful TX
  [28:0] CFID — Common FIFO Buffer ID Field
0x5BC CFDCFPTR — Common FIFO Access Pointer Register
  [31:28] CFDLC — Common FIFO Buffer DLC Field
  [15:0] CFTS — Common FIFO Timestamp Value
0x5C0 CFDCFFDCSTS — Common FIFO Access CANFD Control/Status Register
  [31:16] CFPTR — Common FIFO Buffer Pointer Field
  [9:8] CFIFL — COMMON FIFO Buffer Information Label Field
  [2] CFFDF — CAN FD Format bit
    0=Non CANFD frame received or to transmit; 1=CANFD frame received or to transmit
  [1] CFBRS — Bit Rate Switch bit
    0=CANFD frame received or to transmit with no bit rate switch; 1=CANFD frame received or to transmit with bit rate switch
  [0] CFESI — Error State Indicator bit
    0=CANFD frame received or to transmit by error active node; 1=CANFD frame received or to transmit by error passive node
{0x5C4+4i} CFDCFDF{i} (i=0..15) — Common FIFO Access Data Field {i} Registers
  [31:24] CFDB_HH — Common FIFO Buffer Data Bytes ((p × 4) + 3)
  [23:16] CFDB_HL — Common FIFO Buffer Data Bytes ((p × 4) + 2)
  [15:8] CFDB_LH — Common FIFO Buffer Data Bytes ((p × 4) + 1)
  [7:0] CFDB_LL — Common FIFO Buffer Data Bytes (p × 4)
{0x604+0x4C*i} CFDTMID{i} (i=0..3) — TX Message Buffer ID Registers
  [31] TMIDE — TX Message Buffer IDE bit
    0=STD-ID is transmitted; 1=EXT-ID is transmitted
  [30] TMRTR — TX Message Buffer RTR bit
    0=Data frame; 1=Remote frame
  [29] THLEN — Tx History List Entry
    0=Entry not stored in THL after successful TX; 1=Entry stored in THL after successful TX
  [28:0] TMID — TX Message Buffer ID Field
{0x608+0x4C*i} CFDTMPTR{i} (i=0..3) — TX Message Buffer Pointer Register
  [31:28] TMDLC — TX Message Buffer DLC Field
{0x60C+0x4C*i} CFDTMFDCTR{i} (i=0..3) — TX Message Buffer CANFD Control Register
  [31:16] TMPTR — TX Message Buffer Pointer Field
  [9:8] TMIFL — TX Message Buffer Information Label Field
  [2] TMFDF — CAN FD Format bit
    0=Non CANFD frame to transmit; 1=CANFD frame to transmit
  [1] TMBRS — Bit Rate Switch bit
    0=CANFD frame to transmit with no bit rate switch; 1=CANFD frame to transmit with bit rate switch
  [0] TMESI — Error State Indicator bit
    0=CANFD frame to transmit by error active node; 1=CANFD frame to transmit by error passive node
{0x610+0x4C*i} CFDTMDF{i}_0 (i=0..3) — TX Message Buffer Data Field Register
  [31:24] TMDB_HH — TX Message Buffer Data Byte ((p × 4) + 3)
  [23:16] TMDB_HL — TX Message Buffer Data Byte ((p × 4) + 2)
  [15:8] TMDB_LH — TX Message Buffer Data Byte ((p × 4) + 1)
  [7:0] TMDB_LL — TX Message Buffer Data Byte (p × 4)
{0x614+0x4C*i} CFDTMDF{i}_1 (i=0..3) — TX Message Buffer Data Field Register
  fields as CFDTMDF0_0
{0x618+0x4C*i} CFDTMDF{i}_2 (i=0..3) — TX Message Buffer Data Field Register
  fields as CFDTMDF0_0
{0x61C+0x4C*i} CFDTMDF{i}_3 (i=0..3) — TX Message Buffer Data Field Register
  fields as CFDTMDF0_0
{0x620+0x4C*i} CFDTMDF{i}_4 (i=0..3) — TX Message Buffer Data Field Register
  [31:24] TMDB_HH — TX Message Buffer Data Byte ((p × 4) + 3)
  [23:16] TMDB_HL — TX Message Buffer Data Byte ((p × 4) + 2)
  [15:8] TMDB_LH — TX Message Buffer Data Byte ((p × 4) + 1)
  [7:0] TMDB_LL — TX Message Buffer Data Byte ((p × 4)
{0x624+0x4C*i} CFDTMDF{i}_5 (i=0..3) — TX Message Buffer Data Field Register
  fields as CFDTMDF0_0
{0x628+0x4C*i} CFDTMDF{i}_6 (i=0..3) — TX Message Buffer Data Field Register
  fields as CFDTMDF0_0
{0x62C+0x4C*i} CFDTMDF{i}_7 (i=0..3) — TX Message Buffer Data Field Register
  fields as CFDTMDF0_0
{0x630+0x4C*i} CFDTMDF{i}_8 (i=0..3) — TX Message Buffer Data Field Register
  fields as CFDTMDF0_0
{0x634+0x4C*i} CFDTMDF{i}_9 (i=0..3) — TX Message Buffer Data Field Register
  fields as CFDTMDF0_0
{0x638+0x4C*i} CFDTMDF{i}_10 (i=0..3) — TX Message Buffer Data Field Register
  fields as CFDTMDF0_0
{0x63C+0x4C*i} CFDTMDF{i}_11 (i=0..3) — TX Message Buffer Data Field Register
  fields as CFDTMDF0_0
{0x640+0x4C*i} CFDTMDF{i}_12 (i=0..3) — TX Message Buffer Data Field Register
  fields as CFDTMDF0_4
{0x644+0x4C*i} CFDTMDF{i}_13 (i=0..3) — TX Message Buffer Data Field Register
  fields as CFDTMDF0_4
{0x648+0x4C*i} CFDTMDF{i}_14 (i=0..3) — TX Message Buffer Data Field Register
  fields as CFDTMDF0_4
{0x64C+0x4C*i} CFDTMDF{i}_15 (i=0..3) — TX Message Buffer Data Field Register
  fields as CFDTMDF0_0
0x740 CFDTHLACC0 ro — TX History List Access Register 0
  [31:16] TMTS — Transmit Timestamp
  [4:3] BN — Buffer Number
  [2:0] BT — Buffer Type
    1=Flat TX message buffer; 2=TX FIFO message buffer number; 4=TX Queue message buffer number
0x744 CFDTHLACC1 ro — TX History List Access Register 1
  [17:16] TIFL — Transmit Information Label
  [15:0] TID — Transmit ID
{0x920+0x4C*i} CFDRMID{i} (i=0..7) ro — RX Message Buffer ID Registers
  [31] RMIDE — RX Message Buffer IDE Bit
    0=STD-ID is stored; 1=EXT-ID is stored
  [30] RMRTR — RX Message Buffer RTR Bit
    0=Data frame; 1=Remote frame
  [28:0] RMID — RX Message Buffer ID Field
{0x924+0x4C*i} CFDRMPTR{i} (i=0..7) ro — RX Message Buffer Pointer Registers
  [31:28] RMDLC — RX Message Buffer DLC Field
  [15:0] RMTS — RX Message Buffer Timestamp Field
{0x928+0x4C*i} CFDRMFDSTS{i} (i=0..7) ro — RX Message Buffer CANFD Status Registers
  [31:16] RMPTR — RX Message Buffer Pointer Field
  [9:8] RMIFL — RX Message Buffer Information Label Field
  [2] RMFDF — CAN FD Format bit
    0=Non CANFD frame received; 1=CANFD frame received
  [1] RMBRS — Bit Rate Switch bit
    values as CFDRFFDSTS0.RFBRS
  [0] RMESI — Error State Indicator bit
    values as CFDRFFDSTS0.RFESI
{0x92C+0x4C*i} CFDRMDF{i}_0 (i=0..7) ro — RX Message Buffer Data Field 0 Registers
  [31:24] RMDB_HH — RX Message Buffer Data Byte ((p × 4) + 3)
  [23:16] RMDB_HL — RX Message Buffer Data Byte ((p × 4) + 2)
  [15:8] RMDB_LH — RX Message Buffer Data Byte ((p × 4) + 1)
  [7:0] RMDB_LL — RX Message Buffer Data Byte (p × 4)
{0x930+0x4C*i} CFDRMDF{i}_1 (i=0..7) ro — RX Message Buffer Data Field 1 Registers
  fields as CFDRMDF0_0
{0x934+0x4C*i} CFDRMDF{i}_2 (i=0..7) ro — RX Message Buffer Data Field 2 Registers
  fields as CFDRMDF0_0
{0x938+0x4C*i} CFDRMDF{i}_3 (i=0..7) ro — RX Message Buffer Data Field 3 Registers
  fields as CFDRMDF0_0
{0x93C+0x4C*i} CFDRMDF{i}_4 (i=0..7) ro — RX Message Buffer Data Field 4 Registers
  fields as CFDRMDF0_0
{0x940+0x4C*i} CFDRMDF{i}_5 (i=0..7) ro — RX Message Buffer Data Field 5 Registers
  fields as CFDRMDF0_0
{0x944+0x4C*i} CFDRMDF{i}_6 (i=0..7) ro — RX Message Buffer Data Field 6 Registers
  fields as CFDRMDF0_0
{0x948+0x4C*i} CFDRMDF{i}_7 (i=0..7) ro — RX Message Buffer Data Field 7 Registers
  fields as CFDRMDF0_0
{0x94C+0x4C*i} CFDRMDF{i}_8 (i=0..7) ro — RX Message Buffer Data Field 8 Registers
  fields as CFDRMDF0_0
{0x950+0x4C*i} CFDRMDF{i}_9 (i=0..7) ro — RX Message Buffer Data Field 9 Registers
  fields as CFDRMDF0_0
{0x954+0x4C*i} CFDRMDF{i}_10 (i=0..7) ro — RX Message Buffer Data Field 10 Registers
  fields as CFDRMDF0_0
{0x958+0x4C*i} CFDRMDF{i}_11 (i=0..7) ro — RX Message Buffer Data Field 11 Registers
  fields as CFDRMDF0_0
{0x95C+0x4C*i} CFDRMDF{i}_12 (i=0..7) ro — RX Message Buffer Data Field 12 Registers
  fields as CFDRMDF0_0
{0x960+0x4C*i} CFDRMDF{i}_13 (i=0..7) ro — RX Message Buffer Data Field 13 Registers
  fields as CFDRMDF0_0
{0x964+0x4C*i} CFDRMDF{i}_14 (i=0..7) ro — RX Message Buffer Data Field 14 Registers
  fields as CFDRMDF0_0
{0x968+0x4C*i} CFDRMDF{i}_15 (i=0..7) ro — RX Message Buffer Data Field 15 Registers
  fields as CFDRMDF0_0
{0xAC0+0x4C*i} CFDRMID{i} (i=8..15) ro — RX Message Buffer ID Registers
  fields as CFDRMID0
{0xAC4+0x4C*i} CFDRMPTR{i} (i=8..15) ro — RX Message Buffer Pointer Registers
  fields as CFDRMPTR0
{0xAC8+0x4C*i} CFDRMFDSTS{i} (i=8..15) ro — RX Message Buffer CANFD Status Registers
  fields as CFDRMFDSTS0
{0xACC+0x4C*i} CFDRMDF{i}_0 (i=8..15) ro — RX Message Buffer Data Field 0 Registers
  fields as CFDRMDF0_0
{0xAD0+0x4C*i} CFDRMDF{i}_1 (i=8..15) ro — RX Message Buffer Data Field 1 Registers
  fields as CFDRMDF0_0
{0xAD4+0x4C*i} CFDRMDF{i}_2 (i=8..15) ro — RX Message Buffer Data Field 2 Registers
  fields as CFDRMDF0_0
{0xAD8+0x4C*i} CFDRMDF{i}_3 (i=8..15) ro — RX Message Buffer Data Field 3 Registers
  fields as CFDRMDF0_0
{0xADC+0x4C*i} CFDRMDF{i}_4 (i=8..15) ro — RX Message Buffer Data Field 4 Registers
  fields as CFDRMDF0_0
{0xAE0+0x4C*i} CFDRMDF{i}_5 (i=8..15) ro — RX Message Buffer Data Field 5 Registers
  fields as CFDRMDF0_0
{0xAE4+0x4C*i} CFDRMDF{i}_6 (i=8..15) ro — RX Message Buffer Data Field 6 Registers
  fields as CFDRMDF0_0
{0xAE8+0x4C*i} CFDRMDF{i}_7 (i=8..15) ro — RX Message Buffer Data Field 7 Registers
  fields as CFDRMDF0_0
{0xAEC+0x4C*i} CFDRMDF{i}_8 (i=8..15) ro — RX Message Buffer Data Field 8 Registers
  fields as CFDRMDF0_0
{0xAF0+0x4C*i} CFDRMDF{i}_9 (i=8..15) ro — RX Message Buffer Data Field 9 Registers
  fields as CFDRMDF0_0
{0xAF4+0x4C*i} CFDRMDF{i}_10 (i=8..15) ro — RX Message Buffer Data Field 10 Registers
  fields as CFDRMDF0_0
{0xAF8+0x4C*i} CFDRMDF{i}_11 (i=8..15) ro — RX Message Buffer Data Field 11 Registers
  fields as CFDRMDF0_0
{0xAFC+0x4C*i} CFDRMDF{i}_12 (i=8..15) ro — RX Message Buffer Data Field 12 Registers
  fields as CFDRMDF0_0
{0xB00+0x4C*i} CFDRMDF{i}_13 (i=8..15) ro — RX Message Buffer Data Field 13 Registers
  fields as CFDRMDF0_0
{0xB04+0x4C*i} CFDRMDF{i}_14 (i=8..15) ro — RX Message Buffer Data Field 14 Registers
  fields as CFDRMDF0_0
{0xB08+0x4C*i} CFDRMDF{i}_15 (i=8..15) ro — RX Message Buffer Data Field 15 Registers
  fields as CFDRMDF0_0
{0xC60+0x4C*i} CFDRMID{i} (i=16..23) ro — RX Message Buffer ID Registers
  fields as CFDRMID0
{0xC64+0x4C*i} CFDRMPTR{i} (i=16..23) ro — RX Message Buffer Pointer Registers
  fields as CFDRMPTR0
{0xC68+0x4C*i} CFDRMFDSTS{i} (i=16..23) ro — RX Message Buffer CANFD Status Registers
  fields as CFDRMFDSTS0
{0xC6C+0x4C*i} CFDRMDF{i}_0 (i=16..23) ro — RX Message Buffer Data Field 0 Registers
  fields as CFDRMDF0_0
{0xC70+0x4C*i} CFDRMDF{i}_1 (i=16..23) ro — RX Message Buffer Data Field 1 Registers
  fields as CFDRMDF0_0
{0xC74+0x4C*i} CFDRMDF{i}_2 (i=16..23) ro — RX Message Buffer Data Field 2 Registers
  fields as CFDRMDF0_0
{0xC78+0x4C*i} CFDRMDF{i}_3 (i=16..23) ro — RX Message Buffer Data Field 3 Registers
  fields as CFDRMDF0_0
{0xC7C+0x4C*i} CFDRMDF{i}_4 (i=16..23) ro — RX Message Buffer Data Field 4 Registers
  fields as CFDRMDF0_0
{0xC80+0x4C*i} CFDRMDF{i}_5 (i=16..23) ro — RX Message Buffer Data Field 5 Registers
  fields as CFDRMDF0_0
{0xC84+0x4C*i} CFDRMDF{i}_6 (i=16..23) ro — RX Message Buffer Data Field 6 Registers
  fields as CFDRMDF0_0
{0xC88+0x4C*i} CFDRMDF{i}_7 (i=16..23) ro — RX Message Buffer Data Field 7 Registers
  fields as CFDRMDF0_0
{0xC8C+0x4C*i} CFDRMDF{i}_8 (i=16..23) ro — RX Message Buffer Data Field 8 Registers
  fields as CFDRMDF0_0
{0xC90+0x4C*i} CFDRMDF{i}_9 (i=16..23) ro — RX Message Buffer Data Field 9 Registers
  fields as CFDRMDF0_0
{0xC94+0x4C*i} CFDRMDF{i}_10 (i=16..23) ro — RX Message Buffer Data Field 10 Registers
  fields as CFDRMDF0_0
{0xC98+0x4C*i} CFDRMDF{i}_11 (i=16..23) ro — RX Message Buffer Data Field 11 Registers
  fields as CFDRMDF0_0
{0xC9C+0x4C*i} CFDRMDF{i}_12 (i=16..23) ro — RX Message Buffer Data Field 12 Registers
  fields as CFDRMDF0_0
{0xCA0+0x4C*i} CFDRMDF{i}_13 (i=16..23) ro — RX Message Buffer Data Field 13 Registers
  fields as CFDRMDF0_0
{0xCA4+0x4C*i} CFDRMDF{i}_14 (i=16..23) ro — RX Message Buffer Data Field 14 Registers
  fields as CFDRMDF0_0
{0xCA8+0x4C*i} CFDRMDF{i}_15 (i=16..23) ro — RX Message Buffer Data Field 15 Registers
  fields as CFDRMDF0_0
{0xE00+0x4C*i} CFDRMID{i} (i=24..31) ro — RX Message Buffer ID Registers
  fields as CFDRMID0
{0xE04+0x4C*i} CFDRMPTR{i} (i=24..31) ro — RX Message Buffer Pointer Registers
  fields as CFDRMPTR0
{0xE08+0x4C*i} CFDRMFDSTS{i} (i=24..31) ro — RX Message Buffer CANFD Status Registers
  fields as CFDRMFDSTS0
{0xE0C+0x4C*i} CFDRMDF{i}_0 (i=24..31) ro — RX Message Buffer Data Field 0 Registers
  fields as CFDRMDF0_0
{0xE10+0x4C*i} CFDRMDF{i}_1 (i=24..31) ro — RX Message Buffer Data Field 1 Registers
  fields as CFDRMDF0_0
{0xE14+0x4C*i} CFDRMDF{i}_2 (i=24..31) ro — RX Message Buffer Data Field 2 Registers
  fields as CFDRMDF0_0
{0xE18+0x4C*i} CFDRMDF{i}_3 (i=24..31) ro — RX Message Buffer Data Field 3 Registers
  fields as CFDRMDF0_0
{0xE1C+0x4C*i} CFDRMDF{i}_4 (i=24..31) ro — RX Message Buffer Data Field 4 Registers
  fields as CFDRMDF0_0
{0xE20+0x4C*i} CFDRMDF{i}_5 (i=24..31) ro — RX Message Buffer Data Field 5 Registers
  fields as CFDRMDF0_0
{0xE24+0x4C*i} CFDRMDF{i}_6 (i=24..31) ro — RX Message Buffer Data Field 6 Registers
  fields as CFDRMDF0_0
{0xE28+0x4C*i} CFDRMDF{i}_7 (i=24..31) ro — RX Message Buffer Data Field 7 Registers
  fields as CFDRMDF0_0
{0xE2C+0x4C*i} CFDRMDF{i}_8 (i=24..31) ro — RX Message Buffer Data Field 8 Registers
  fields as CFDRMDF0_0
{0xE30+0x4C*i} CFDRMDF{i}_9 (i=24..31) ro — RX Message Buffer Data Field 9 Registers
  fields as CFDRMDF0_0
{0xE34+0x4C*i} CFDRMDF{i}_10 (i=24..31) ro — RX Message Buffer Data Field 10 Registers
  fields as CFDRMDF0_0
{0xE38+0x4C*i} CFDRMDF{i}_11 (i=24..31) ro — RX Message Buffer Data Field 11 Registers
  fields as CFDRMDF0_0
{0xE3C+0x4C*i} CFDRMDF{i}_12 (i=24..31) ro — RX Message Buffer Data Field 12 Registers
  fields as CFDRMDF0_0
{0xE40+0x4C*i} CFDRMDF{i}_13 (i=24..31) ro — RX Message Buffer Data Field 13 Registers
  fields as CFDRMDF0_0
{0xE44+0x4C*i} CFDRMDF{i}_14 (i=24..31) ro — RX Message Buffer Data Field 14 Registers
  fields as CFDRMDF0_0
{0xE48+0x4C*i} CFDRMDF{i}_15 (i=24..31) ro — RX Message Buffer Data Field 15 Registers
  fields as CFDRMDF0_0
